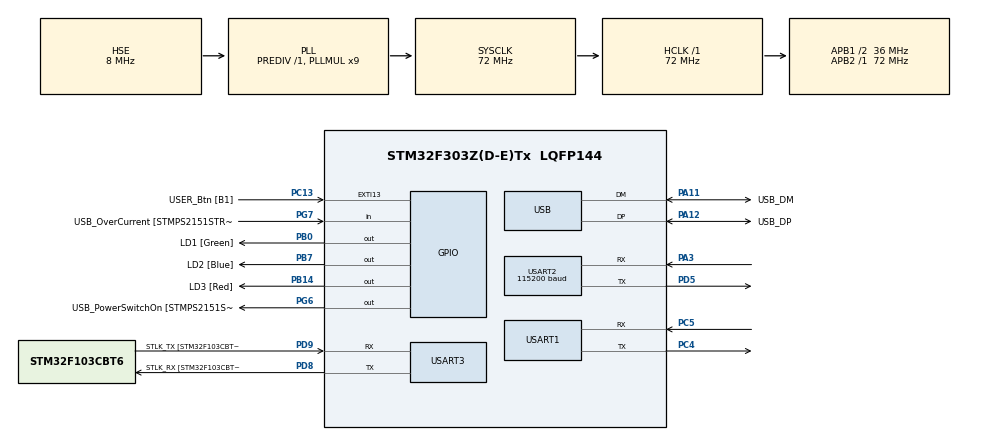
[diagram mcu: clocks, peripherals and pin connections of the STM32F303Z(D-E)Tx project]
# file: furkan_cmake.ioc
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Dma.Request0=USART1_RX
Dma.Request1=USART1_TX
Dma.USART1_RX.0.Direction=DMA_PERIPH_TO_MEMORY
Dma.USART1_RX.0.Instance=DMA1_Channel5
Dma.USART1_RX.0.MemDataAlignment=DMA_MDATAALIGN_BYTE
Dma.USART1_RX.0.MemInc=DMA_MINC_ENABLE
Dma.USART1_RX.0.Mode=DMA_NORMAL
Dma.USART1_RX.0.PeriphDataAlignment=DMA_PDATAALIGN_BYTE
Dma.USART1_RX.0.PeriphInc=DMA_PINC_DISABLE
Dma.USART1_RX.0.Priority=DMA_PRIORITY_LOW
Dma.USART1_TX.1.Direction=DMA_MEMORY_TO_PERIPH
Dma.USART1_TX.1.Instance=DMA1_Channel4
Dma.USART1_TX.1.MemDataAlignment=DMA_MDATAALIGN_BYTE
Dma.USART1_TX.1.MemInc=DMA_MINC_ENABLE
Dma.USART1_TX.1.Mode=DMA_NORMAL
Dma.USART1_TX.1.PeriphDataAlignment=DMA_PDATAALIGN_BYTE
Dma.USART1_TX.1.PeriphInc=DMA_PINC_DISABLE
Dma.USART1_TX.1.Priority=DMA_PRIORITY_LOW
Mcu.Family=STM32F3
Mcu.Name=STM32F303Z(D-E)Tx
Mcu.Package=LQFP144
NVIC.DMA1_Channel4_IRQn=true\:0\:0\:false\:false\:true\:false\:true\:true
NVIC.DMA1_Channel5_IRQn=true\:0\:0\:false\:false\:true\:false\:true\:true
NVIC.PriorityGroup=NVIC_PRIORITYGROUP_4
NVIC.USART2_IRQn=true\:0\:0\:false\:false\:true\:true\:true\:true
NVIC.USB_LP_CAN_RX0_IRQn=true\:0\:0\:false\:false\:true\:true\:true\:true
PA11.GPIO_Label=USB_DM
PA11.Mode=Device
PA11.Signal=USB_DM
PA12.GPIO_Label=USB_DP
PA12.Mode=Device
PA12.Signal=USB_DP
PA13.GPIO_Label=TMS
PA13.Mode=Serial_Wire
PA13.Signal=SYS_JTMS-SWDIO
PA14.GPIO_Label=TCK
PA14.Mode=Serial_Wire
PA14.Signal=SYS_JTCK-SWCLK
PA3.Mode=Asynchronous
PA3.Signal=USART2_RX
PB0.GPIO_Label=LD1 [Green]
PB0.Signal=GPIO_Output
PB14.GPIO_Label=LD3 [Red]
PB14.Signal=GPIO_Output
PB3.GPIO_Label=SWO
PB3.Signal=SYS_JTDO-TRACESWO
PB7.GPIO_Label=LD2 [Blue]
PB7.Signal=GPIO_Output
PC13.GPIO_Label=USER_Btn [B1]
PC13.Signal=GPXTI13
PC14-OSC32_IN.Mode=LSE-External-Oscillator
PC14-OSC32_IN.Signal=RCC_OSC32_IN
PC15-OSC32_OUT.Mode=LSE-External-Oscillator
PC15-OSC32_OUT.Signal=RCC_OSC32_OUT
PC4.Mode=Asynchronous
PC4.Signal=USART1_TX
PC5.Mode=Asynchronous
PC5.Signal=USART1_RX
PD5.Mode=Asynchronous
PD5.Signal=USART2_TX
PD8.GPIO_Label=STLK_RX [STM32F103CBT6_PA3]
PD8.Mode=Asynchronous
PD8.Signal=USART3_TX
PD9.GPIO_Label=STLK_TX [STM32F103CBT6_PA2]
PD9.Mode=Asynchronous
PD9.Signal=USART3_RX
PF0-OSC_IN.GPIO_Label=MCO [STM32F103CBT6_PA8]
PF0-OSC_IN.Mode=HSE-External-Clock-Source
PF0-OSC_IN.Signal=RCC_OSC_IN
PG6.GPIO_Label=USB_PowerSwitchOn [STMPS2151STR_EN]
PG6.Signal=GPIO_Output
PG7.GPIO_Label=USB_OverCurrent [STMPS2151STR_FAULT]
PG7.Signal=GPIO_Input
ProjectManager.HeapSize=0x200
ProjectManager.StackSize=0x400
ProjectManager.TargetToolchain=CMake
RCC.AHBFreq_Value=72000000
RCC.APB1CLKDivider=RCC_HCLK_DIV2
RCC.APB1Freq_Value=36000000
RCC.APB1TimFreq_Value=72000000
RCC.APB2Freq_Value=72000000
RCC.APB2TimFreq_Value=72000000
RCC.CortexFreq_Value=72000000
RCC.HCLKFreq_Value=72000000
RCC.HSE_VALUE=8000000
RCC.HSI_VALUE=8000000
RCC.PLLMUL=RCC_PLL_MUL9
RCC.PRESCALERUSB=RCC_USBCLKSOURCE_PLL_DIV1_5
RCC.SYSCLKFreq_VALUE=72000000
RCC.SYSCLKSourceVirtual=RCC_SYSCLKSOURCE_PLLCLK
RCC.USBFreq_Value=48000000
USART1.VirtualMode-Asynchronous=VM_ASYNC
USART2.BaudRate=115200
USART2.VirtualMode-Asynchronous=VM_ASYNC
USART3.VirtualMode-Asynchronous=VM_ASYNC
VP_RTC_VS_RTC_Activate.Mode=RTC_Enabled
board=NUCLEO-F303ZE

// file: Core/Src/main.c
/* USER CODE BEGIN Header */
/**
  ******************************************************************************
  * @file           : main.c
  * @brief          : Main program body
  ******************************************************************************
  * @attention
  *
  * Copyright (c) 2025 STMicroelectronics.
  * All rights reserved.
  *
  * This software is licensed under terms that can be found in the LICENSE file
  * in the root directory of this software component.
  * If no LICENSE file comes with this software, it is provided AS-IS.
  *
  ******************************************************************************
  */
/* USER CODE END Header */
#include "main.h"

RTC_HandleTypeDef hrtc;

UART_HandleTypeDef huart1;
UART_HandleTypeDef huart2;
UART_HandleTypeDef huart3;
DMA_HandleTypeDef hdma_usart1_rx;
DMA_HandleTypeDef hdma_usart1_tx;

PCD_HandleTypeDef hpcd_USB_FS;

void SystemClock_Config(void);
static void MX_GPIO_Init(void);
static void MX_DMA_Init(void);
static void MX_RTC_Init(void);
static void MX_USART3_UART_Init(void);
static void MX_USB_PCD_Init(void);
static void MX_USART1_UART_Init(void);
static void MX_USART2_UART_Init(void);

/* USER CODE BEGIN 0 */

#ifdef USE_CPP_MAIN
void board_init(void)
{

#else

/* USER CODE END 0 */

int main(void)
{

  /* USER CODE BEGIN 1 */
#endif
  /* USER CODE END 1 */

  /* MCU Configuration--------------------------------------------------------*/

  /* Reset of all peripherals, Initializes the Flash interface and the Systick. */
  HAL_Init();

  /* Configure the system clock */
  SystemClock_Config();

  /* Initialize all configured peripherals */
  MX_GPIO_Init();
  MX_DMA_Init();
  MX_RTC_Init();
  MX_USART3_UART_Init();
  MX_USB_PCD_Init();
  MX_USART1_UART_Init();
  MX_USART2_UART_Init();
  /* USER CODE BEGIN 2 */

  #ifndef USE_CPP_MAIN
  /* USER CODE END 2 */

  /* Infinite loop */
  /* USER CODE BEGIN WHILE */
  while (1)
  {

    /*
    HAL_GPIO_TogglePin(GPIOB, GPIO_PIN_0);
    HAL_Delay(500);
    HAL_GPIO_TogglePin(GPIOB, GPIO_PIN_7);
    HAL_Delay(500);
    HAL_GPIO_TogglePin(GPIOB, GPIO_PIN_14);
    HAL_Delay(500);
    */
    /* USER CODE END WHILE */

    /* USER CODE BEGIN 3 */
  }
  #endif

  /* USER CODE END 3 */
}

void SystemClock_Config(void)
{
  RCC_OscInitTypeDef RCC_OscInitStruct = {0};
  RCC_ClkInitTypeDef RCC_ClkInitStruct = {0};
  RCC_PeriphCLKInitTypeDef PeriphClkInit = {0};

  /** Initializes the RCC Oscillators according to the specified parameters
  * in the RCC_OscInitTypeDef structure.
  */
  RCC_OscInitStruct.OscillatorType = RCC_OSCILLATORTYPE_LSI|RCC_OSCILLATORTYPE_HSE;
  RCC_OscInitStruct.HSEState = RCC_HSE_BYPASS;
  RCC_OscInitStruct.HSIState = RCC_HSI_ON;
  RCC_OscInitStruct.LSIState = RCC_LSI_ON;
  RCC_OscInitStruct.PLL.PLLState = RCC_PLL_ON;
  RCC_OscInitStruct.PLL.PLLSource = RCC_PLLSOURCE_HSE;
  RCC_OscInitStruct.PLL.PLLMUL = RCC_PLL_MUL9;
  RCC_OscInitStruct.PLL.PREDIV = RCC_PREDIV_DIV1;
  if (HAL_RCC_OscConfig(&RCC_OscInitStruct) != HAL_OK)
  {
    Error_Handler();
  }

  /** Initializes the CPU, AHB and APB buses clocks
  */
  RCC_ClkInitStruct.ClockType = RCC_CLOCKTYPE_HCLK|RCC_CLOCKTYPE_SYSCLK
                              |RCC_CLOCKTYPE_PCLK1|RCC_CLOCKTYPE_PCLK2;
  RCC_ClkInitStruct.SYSCLKSource = RCC_SYSCLKSOURCE_PLLCLK;
  RCC_ClkInitStruct.AHBCLKDivider = RCC_SYSCLK_DIV1;
  RCC_ClkInitStruct.APB1CLKDivider = RCC_HCLK_DIV2;
  RCC_ClkInitStruct.APB2CLKDivider = RCC_HCLK_DIV1;

  if (HAL_RCC_ClockConfig(&RCC_ClkInitStruct, FLASH_LATENCY_2) != HAL_OK)
  {
    Error_Handler();
  }
  PeriphClkInit.PeriphClockSelection = RCC_PERIPHCLK_USB|RCC_PERIPHCLK_USART1
                              |RCC_PERIPHCLK_USART2|RCC_PERIPHCLK_USART3
                              |RCC_PERIPHCLK_RTC;
  PeriphClkInit.Usart1ClockSelection = RCC_USART1CLKSOURCE_PCLK2;
  PeriphClkInit.Usart2ClockSelection = RCC_USART2CLKSOURCE_PCLK1;
  PeriphClkInit.Usart3ClockSelection = RCC_USART3CLKSOURCE_PCLK1;
  PeriphClkInit.RTCClockSelection = RCC_RTCCLKSOURCE_LSI;
  PeriphClkInit.USBClockSelection = RCC_USBCLKSOURCE_PLL_DIV1_5;
  if (HAL_RCCEx_PeriphCLKConfig(&PeriphClkInit) != HAL_OK)
  {
    Error_Handler();
  }
}

static void MX_RTC_Init(void)
{

  /** Initialize RTC Only
  */
  hrtc.Instance = RTC;
  hrtc.Init.HourFormat = RTC_HOURFORMAT_24;
  hrtc.Init.AsynchPrediv = 127;
  hrtc.Init.SynchPrediv = 255;
  hrtc.Init.OutPut = RTC_OUTPUT_DISABLE;
  hrtc.Init.OutPutPolarity = RTC_OUTPUT_POLARITY_HIGH;
  hrtc.Init.OutPutType = RTC_OUTPUT_TYPE_OPENDRAIN;
  if (HAL_RTC_Init(&hrtc) != HAL_OK)
  {
    Error_Handler();
  }

}

static void MX_USART1_UART_Init(void)
{

  huart1.Instance = USART1;
  huart1.Init.BaudRate = 38400;
  huart1.Init.WordLength = UART_WORDLENGTH_8B;
  huart1.Init.StopBits = UART_STOPBITS_1;
  huart1.Init.Parity = UART_PARITY_NONE;
  huart1.Init.Mode = UART_MODE_TX_RX;
  huart1.Init.HwFlowCtl = UART_HWCONTROL_NONE;
  huart1.Init.OverSampling = UART_OVERSAMPLING_16;
  huart1.Init.OneBitSampling = UART_ONE_BIT_SAMPLE_DISABLE;
  huart1.AdvancedInit.AdvFeatureInit = UART_ADVFEATURE_NO_INIT;
  if (HAL_UART_Init(&huart1) != HAL_OK)
  {
    Error_Handler();
  }

}

static void MX_USART2_UART_Init(void)
{

  huart2.Instance = USART2;
  huart2.Init.BaudRate = 115200;
  huart2.Init.WordLength = UART_WORDLENGTH_8B;
  huart2.Init.StopBits = UART_STOPBITS_1;
  huart2.Init.Parity = UART_PARITY_NONE;
  huart2.Init.Mode = UART_MODE_TX_RX;
  huart2.Init.HwFlowCtl = UART_HWCONTROL_NONE;
  huart2.Init.OverSampling = UART_OVERSAMPLING_16;
  huart2.Init.OneBitSampling = UART_ONE_BIT_SAMPLE_DISABLE;
  huart2.AdvancedInit.AdvFeatureInit = UART_ADVFEATURE_NO_INIT;
  if (HAL_UART_Init(&huart2) != HAL_OK)
  {
    Error_Handler();
  }

}

static void MX_USART3_UART_Init(void)
{

  huart3.Instance = USART3;
  huart3.Init.BaudRate = 38400;
  huart3.Init.WordLength = UART_WORDLENGTH_8B;
  huart3.Init.StopBits = UART_STOPBITS_1;
  huart3.Init.Parity = UART_PARITY_NONE;
  huart3.Init.Mode = UART_MODE_TX_RX;
  huart3.Init.HwFlowCtl = UART_HWCONTROL_NONE;
  huart3.Init.OverSampling = UART_OVERSAMPLING_16;
  huart3.Init.OneBitSampling = UART_ONE_BIT_SAMPLE_DISABLE;
  huart3.AdvancedInit.AdvFeatureInit = UART_ADVFEATURE_NO_INIT;
  if (HAL_UART_Init(&huart3) != HAL_OK)
  {
    Error_Handler();
  }

}

static void MX_USB_PCD_Init(void)
{

  hpcd_USB_FS.Instance = USB;
  hpcd_USB_FS.Init.dev_endpoints = 8;
  hpcd_USB_FS.Init.speed = PCD_SPEED_FULL;
  hpcd_USB_FS.Init.phy_itface = PCD_PHY_EMBEDDED;
  hpcd_USB_FS.Init.low_power_enable = DISABLE;
  hpcd_USB_FS.Init.lpm_enable = DISABLE;
  hpcd_USB_FS.Init.battery_charging_enable = DISABLE;
  if (HAL_PCD_Init(&hpcd_USB_FS) != HAL_OK)
  {
    Error_Handler();
  }

}

static void MX_DMA_Init(void)
{

  /* DMA controller clock enable */
  __HAL_RCC_DMA1_CLK_ENABLE();

  /* DMA interrupt init */
  /* DMA1_Channel4_IRQn interrupt configuration */
  HAL_NVIC_SetPriority(DMA1_Channel4_IRQn, 0, 0);
  HAL_NVIC_EnableIRQ(DMA1_Channel4_IRQn);
  /* DMA1_Channel5_IRQn interrupt configuration */
  HAL_NVIC_SetPriority(DMA1_Channel5_IRQn, 0, 0);
  HAL_NVIC_EnableIRQ(DMA1_Channel5_IRQn);

}

static void MX_GPIO_Init(void)
{
  GPIO_InitTypeDef GPIO_InitStruct = {0};

  /* GPIO Ports Clock Enable */
  __HAL_RCC_GPIOC_CLK_ENABLE();
  __HAL_RCC_GPIOF_CLK_ENABLE();
  __HAL_RCC_GPIOA_CLK_ENABLE();
  __HAL_RCC_GPIOB_CLK_ENABLE();
  __HAL_RCC_GPIOD_CLK_ENABLE();
  __HAL_RCC_GPIOG_CLK_ENABLE();

  /*Configure GPIO pin Output Level */
  HAL_GPIO_WritePin(GPIOB, LD1_Pin|LD3_Pin|LD2_Pin, GPIO_PIN_RESET);

  /*Configure GPIO pin Output Level */
  HAL_GPIO_WritePin(USB_PowerSwitchOn_GPIO_Port, USB_PowerSwitchOn_Pin, GPIO_PIN_RESET);

  /*Configure GPIO pin : USER_Btn_Pin */
  GPIO_InitStruct.Pin = USER_Btn_Pin;
  GPIO_InitStruct.Mode = GPIO_MODE_IT_RISING;
  GPIO_InitStruct.Pull = GPIO_NOPULL;
  HAL_GPIO_Init(USER_Btn_GPIO_Port, &GPIO_InitStruct);

  /*Configure GPIO pins : LD1_Pin LD3_Pin LD2_Pin */
  GPIO_InitStruct.Pin = LD1_Pin|LD3_Pin|LD2_Pin;
  GPIO_InitStruct.Mode = GPIO_MODE_OUTPUT_PP;
  GPIO_InitStruct.Pull = GPIO_NOPULL;
  GPIO_InitStruct.Speed = GPIO_SPEED_FREQ_LOW;
  HAL_GPIO_Init(GPIOB, &GPIO_InitStruct);

  /*Configure GPIO pin : USB_PowerSwitchOn_Pin */
  GPIO_InitStruct.Pin = USB_PowerSwitchOn_Pin;
  GPIO_InitStruct.Mode = GPIO_MODE_OUTPUT_PP;
  GPIO_InitStruct.Pull = GPIO_NOPULL;
  GPIO_InitStruct.Speed = GPIO_SPEED_FREQ_LOW;
  HAL_GPIO_Init(USB_PowerSwitchOn_GPIO_Port, &GPIO_InitStruct);

  /*Configure GPIO pin : USB_OverCurrent_Pin */
  GPIO_InitStruct.Pin = USB_OverCurrent_Pin;
  GPIO_InitStruct.Mode = GPIO_MODE_INPUT;
  GPIO_InitStruct.Pull = GPIO_NOPULL;
  HAL_GPIO_Init(USB_OverCurrent_GPIO_Port, &GPIO_InitStruct);

}

void Error_Handler(void)
{
  __disable_irq();
  while (1)
  {
  }
}
